VERSION ""

NS_ :

BS_:

BU_: Output_ECU Logic_ECU Input_ECU

BO_ 5 Output_data: 8 Vector__XXX

BO_ 4 Logic_data: 3 Logic_ECU
 SG_ gyrologic : 8|8@1- (1,0) [0|0] "" Vector__XXX

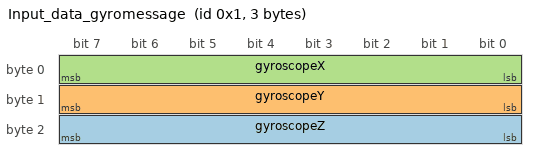
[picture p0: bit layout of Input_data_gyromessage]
BO_ 1 Input_data_gyromessage: 3 Input_ECU
 SG_ gyroscopeZ : 16|8@1- (1,0) [0|0] "" Vector__XXX
 SG_ gyroscopeY : 8|8@1- (1,0) [0|0] "" Vector__XXX
 SG_ gyroscopeX : 0|8@1- (1,0) [0|0] "" Vector__XXX

BA_DEF_  "BusType" STRING ;
BA_DEF_DEF_  "BusType" "CAN";
